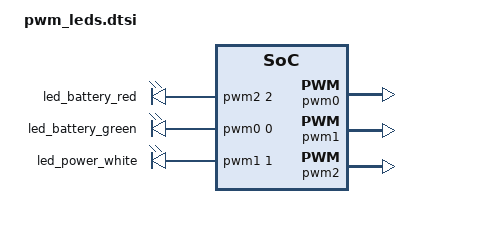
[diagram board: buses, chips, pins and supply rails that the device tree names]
/* Copyright 2024 The ChromiumOS Authors
 * Use of this source code is governed by a BSD-style license that can be
 * found in the LICENSE file.
 */

/ {
	pwmleds {
		compatible = "pwm-leds";
		led_battery_red: ec_led1_odl {
			pwms = <&pwm2 2 PWM_HZ(324) PWM_POLARITY_INVERTED>;
		};
		led_battery_green: ec_led2_odl {
			pwms = <&pwm0 0 PWM_HZ(324) PWM_POLARITY_INVERTED>;
		};
		led_power_white: ec_led3_odl {
			pwms = <&pwm1 1 PWM_HZ(324) PWM_POLARITY_INVERTED>;
		};
	};
};

/* Enable LEDs to work while CPU suspended */

/* Red LED */
&pwm0_gpc3 {
	drive-open-drain;
};

&pwm0 {
	status = "okay";
	clock-bus = "NPCX_CLOCK_BUS_LFCLK";
	pinctrl-0 = <&pwm0_gpc3>;
	pinctrl-names = "default";
};

/* Green LED */
&pwm1_gpc2 {
	drive-open-drain;
};

&pwm1 {
	status = "okay";
	clock-bus = "NPCX_CLOCK_BUS_LFCLK";
	pinctrl-0 = <&pwm1_gpc2>;
	pinctrl-names = "default";
};

/* White LED */
&pwm2_gpc4 {
	drive-open-drain;
};

&pwm2 {
	status = "okay";
	clock-bus = "NPCX_CLOCK_BUS_LFCLK";
	pinctrl-0 = <&pwm2_gpc4>;
	pinctrl-names = "default";
};
